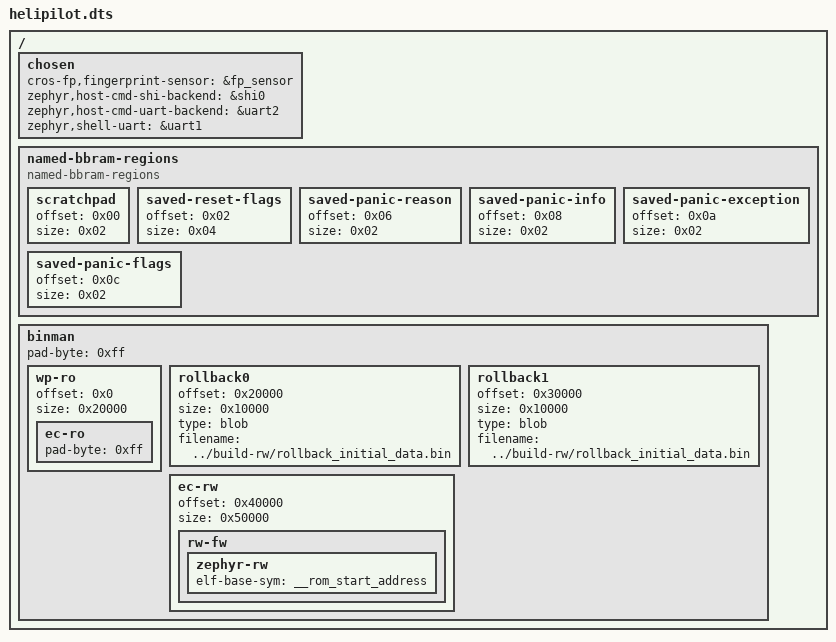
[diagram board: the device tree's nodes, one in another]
/* Copyright 2025 The ChromiumOS Authors.
 * Use of this source code is governed by a BSD-style license that can be
 * found in the LICENSE file.
 */

#include "soc.dtsi"
#include "gpio.dtsi"
#include "rwsig.dtsi"

/ {
	chosen {
		cros-fp,fingerprint-sensor = &fp_sensor;
		zephyr,host-cmd-shi-backend = &shi0;
		zephyr,host-cmd-uart-backend = &uart2;
		zephyr,shell-uart = &uart1;
	};

	named-bbram-regions {
		compatible = "named-bbram-regions";

		scratchpad {
			offset = <0x00>;
			size = <0x02>;
		};
		saved-reset-flags {
			offset = <0x02>;
			size = <0x04>;
		};
		saved-panic-reason {
			offset = <0x06>;
			size = <0x02>;
		};
		saved-panic-info {
			offset = <0x08>;
			size = <0x02>;
		};
		saved-panic-exception {
			offset = <0x0a>;
			size = <0x02>;
		};
		saved-panic-flags {
			offset = <0x0c>;
			size = <0x02>;
		};
	};

	binman {
		/* First 128 kB (uniform 4 kB sectors) used for RO */
		wp-ro {
			offset = <0x0>;
			size = <0x20000>;
			ec-ro {
				pad-byte = <0xff>;
			};
		};

		/* Two rollback sections (64 kB each) */
		rollback0 {
			offset = <0x20000>;
			size = <0x10000>;
			type = "blob";
			filename = "../build-rw/rollback_initial_data.bin";
		};

		rollback1 {
			offset = <0x30000>;
			size = <0x10000>;
			type = "blob";
			filename = "../build-rw/rollback_initial_data.bin";
		};

		/* 320 kB used for RW - helipilot ECOS flash size */
		ec-rw {
			offset = <0x40000>;
			size = <0x50000>;
			rw-fw {
				/*
				 * Clang doesn't emit STT_SECTION symbols (also
				 * called 'section symbols'), so 'rom_start'
				 * symbol is not available. Fortunately, Zephyr
				 * linker scripts provide '__rom_start_address'
				 * symbol which points to the beginning of
				 * 'rom_start' section.
				 */
				zephyr-rw {
					elf-base-sym = "__rom_start_address";
				};
			};
		};
		pad-byte = <0xff>;
	};
};
